# jbr_1986BE9x register map
Registers are 32-bit, access not given, no defined reset value unless marked. A register's access mark holds for its fields unless they carry their own. Addresses are absolute; registers are grouped by the start of their names; [hi:lo] are bit positions.

## IWDG
0x40068000 IWDG_KR 16-bit
  [15:0] KEY
0x40068004 IWDG_PR 16-bit
  [2:0] PR
0x40068008 IWDG_RLR 16-bit
  [11:0] RLR
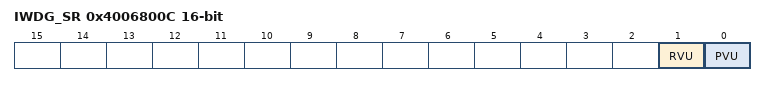
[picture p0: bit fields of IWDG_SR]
0x4006800C IWDG_SR 16-bit
  [1] RVU, [0] PVU

## WWDG
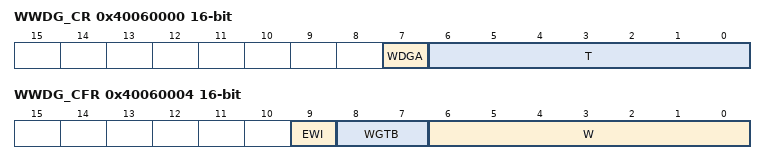
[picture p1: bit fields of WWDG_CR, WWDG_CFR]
0x40060000 WWDG_CR 16-bit
  [7] WDGA, [6:0] T
0x40060004 WWDG_CFR 16-bit
  [9] EWI, [8:7] WGTB, [6:0] W
0x40060008 WWDG_SR 16-bit
  [0] EWIF

## I2C
0x40050000 I2C_PRL
  [7:0] PR
0x40050004 I2C_PRH
  [7:0] PR
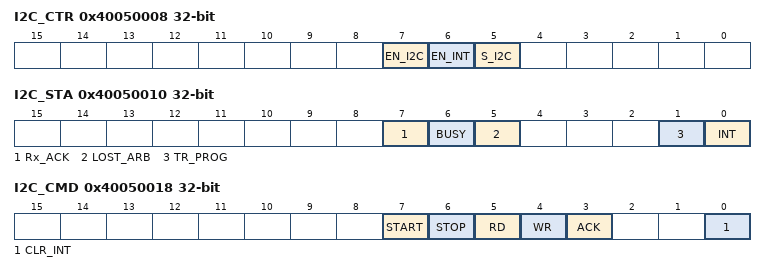
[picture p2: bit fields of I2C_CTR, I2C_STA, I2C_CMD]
0x40050008 I2C_CTR
  [7] EN_I2C, [6] EN_INT, [5] S_I2C
0x4005000C I2C_RXD
  [7:0] RXD
0x40050010 I2C_STA
  [7] Rx_ACK, [6] BUSY, [5] LOST_ARB, [1] TR_PROG, [0] INT
0x40050014 I2C_TXD
  [7:0] TXD
0x40050018 I2C_CMD
  [7] START, [6] STOP, [5] RD, [4] WR, [3] ACK, [0] CLR_INT

## SSP1
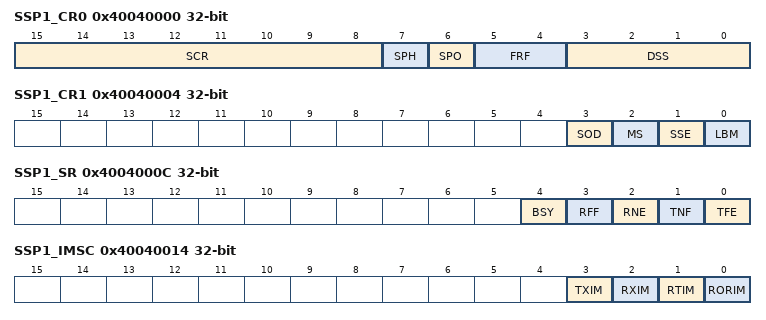
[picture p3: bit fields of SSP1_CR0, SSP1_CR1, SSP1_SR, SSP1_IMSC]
0x40040000 SSP1_CR0
  [15:8] SCR, [7] SPH, [6] SPO, [5:4] FRF, [3:0] DSS
0x40040004 SSP1_CR1
  [3] SOD, [2] MS, [1] SSE, [0] LBM
0x40040008 SSP1_DR
  [15:0] DATA
0x4004000C SSP1_SR
  [4] BSY, [3] RFF, [2] RNE, [1] TNF, [0] TFE
0x40040010 SSP1_CPSR
  [7:0] CPSDVSR
0x40040014 SSP1_IMSC
  [3] TXIM, [2] RXIM, [1] RTIM, [0] RORIM
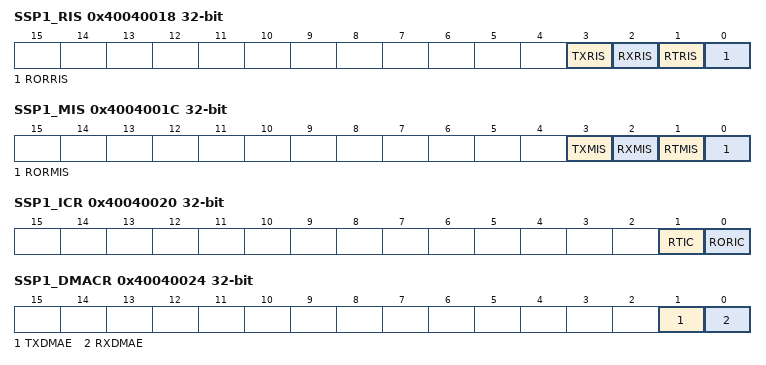
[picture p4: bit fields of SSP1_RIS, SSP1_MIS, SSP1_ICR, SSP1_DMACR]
0x40040018 SSP1_RIS
  [3] TXRIS, [2] RXRIS, [1] RTRIS, [0] RORRIS
0x4004001C SSP1_MIS
  [3] TXMIS, [2] RXMIS, [1] RTMIS, [0] RORMIS
0x40040020 SSP1_ICR
  [1] RTIC, [0] RORIC
0x40040024 SSP1_DMACR
  [1] TXDMAE, [0] RXDMAE

## SSP2
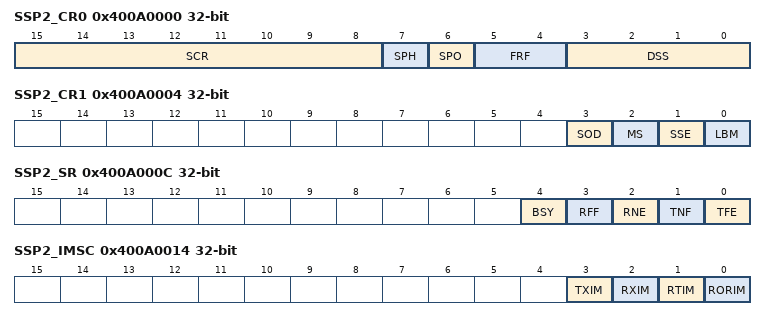
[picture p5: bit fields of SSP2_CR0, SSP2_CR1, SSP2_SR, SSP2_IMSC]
0x400A0000 SSP2_CR0
  [15:8] SCR, [7] SPH, [6] SPO, [5:4] FRF, [3:0] DSS
0x400A0004 SSP2_CR1
  [3] SOD, [2] MS, [1] SSE, [0] LBM
0x400A0008 SSP2_DR
  [15:0] DATA
0x400A000C SSP2_SR
  [4] BSY, [3] RFF, [2] RNE, [1] TNF, [0] TFE
0x400A0010 SSP2_CPSR
  [7:0] CPSDVSR
0x400A0014 SSP2_IMSC
  [3] TXIM, [2] RXIM, [1] RTIM, [0] RORIM
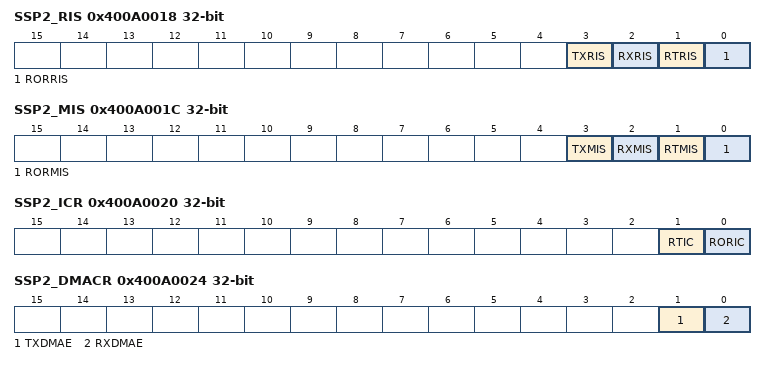
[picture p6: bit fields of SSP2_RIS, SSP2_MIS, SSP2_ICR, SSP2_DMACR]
0x400A0018 SSP2_RIS
  [3] TXRIS, [2] RXRIS, [1] RTRIS, [0] RORRIS
0x400A001C SSP2_MIS
  [3] TXMIS, [2] RXMIS, [1] RTMIS, [0] RORMIS
0x400A0020 SSP2_ICR
  [1] RTIC, [0] RORIC
0x400A0024 SSP2_DMACR
  [1] TXDMAE, [0] RXDMAE

## COMP
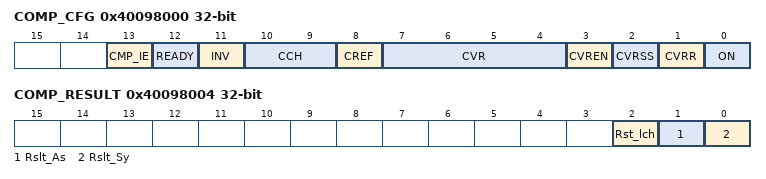
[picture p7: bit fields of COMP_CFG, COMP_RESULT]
0x40098000 COMP_CFG
  [13] CMP_IE, [12] READY, [11] INV, [10:9] CCH, [8] CREF, [7:4] CVR, [3] CVREN, [2] CVRSS, [1] CVRR, [0] ON
0x40098004 COMP_RESULT
  [2] Rst_lch, [1] Rslt_As, [0] Rslt_Sy
0x40098008 COMP_RESULT_LATCH
  [15:0] Rst_lch

## SFR
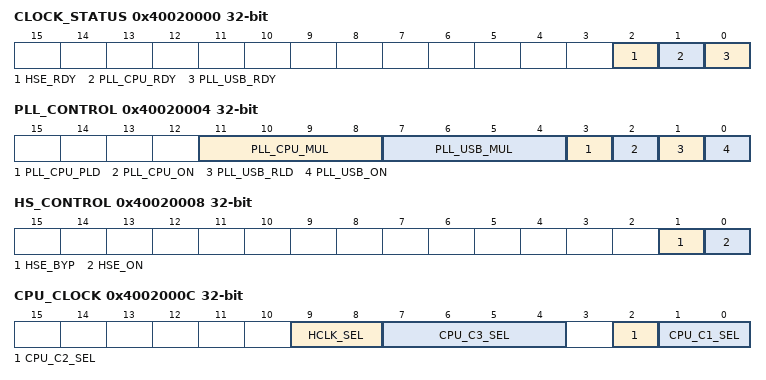
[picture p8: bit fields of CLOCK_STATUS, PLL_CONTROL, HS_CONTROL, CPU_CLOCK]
0x40020000 CLOCK_STATUS
  [2] HSE_RDY, [1] PLL_CPU_RDY, [0] PLL_USB_RDY
0x40020004 PLL_CONTROL
  [11:8] PLL_CPU_MUL, [7:4] PLL_USB_MUL, [3] PLL_CPU_PLD, [2] PLL_CPU_ON, [1] PLL_USB_RLD, [0] PLL_USB_ON
0x40020008 HS_CONTROL
  [1] HSE_BYP, [0] HSE_ON
0x4002000C CPU_CLOCK
  [9:8] HCLK_SEL, [7:4] CPU_C3_SEL, [2] CPU_C2_SEL, [1:0] CPU_C1_SEL
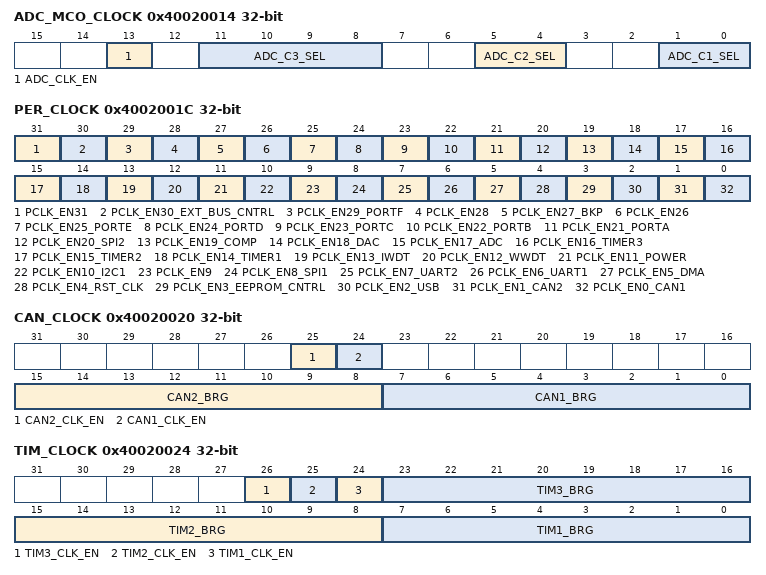
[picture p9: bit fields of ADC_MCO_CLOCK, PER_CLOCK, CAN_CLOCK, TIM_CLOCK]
0x40020014 ADC_MCO_CLOCK
  [13] ADC_CLK_EN, [11:8] ADC_C3_SEL, [5:4] ADC_C2_SEL, [1:0] ADC_C1_SEL
0x4002001C PER_CLOCK
  [31] PCLK_EN31, [30] PCLK_EN30_EXT_BUS_CNTRL, [29] PCLK_EN29_PORTF, [28] PCLK_EN28, [27] PCLK_EN27_BKP, [26] PCLK_EN26, [25] PCLK_EN25_PORTE, [24] PCLK_EN24_PORTD, [23] PCLK_EN23_PORTC, [22] PCLK_EN22_PORTB, [21] PCLK_EN21_PORTA, [20] PCLK_EN20_SPI2, [19] PCLK_EN19_COMP, [18] PCLK_EN18_DAC, [17] PCLK_EN17_ADC, [16] PCLK_EN16_TIMER3, [15] PCLK_EN15_TIMER2, [14] PCLK_EN14_TIMER1, [13] PCLK_EN13_IWDT, [12] PCLK_EN12_WWDT, [11] PCLK_EN11_POWER, [10] PCLK_EN10_I2C1, [9] PCLK_EN9, [8] PCLK_EN8_SPI1, [7] PCLK_EN7_UART2, [6] PCLK_EN6_UART1, [5] PCLK_EN5_DMA, [4] PCLK_EN4_RST_CLK, [3] PCLK_EN3_EEPROM_CNTRL, [2] PCLK_EN2_USB, [1] PCLK_EN1_CAN2, [0] PCLK_EN0_CAN1
0x40020020 CAN_CLOCK
  [25] CAN2_CLK_EN, [24] CAN1_CLK_EN, [15:8] CAN2_BRG, [7:0] CAN1_BRG
0x40020024 TIM_CLOCK
  [26] TIM3_CLK_EN, [25] TIM2_CLK_EN, [24] TIM1_CLK_EN, [23:16] TIM3_BRG, [15:8] TIM2_BRG, [7:0] TIM1_BRG
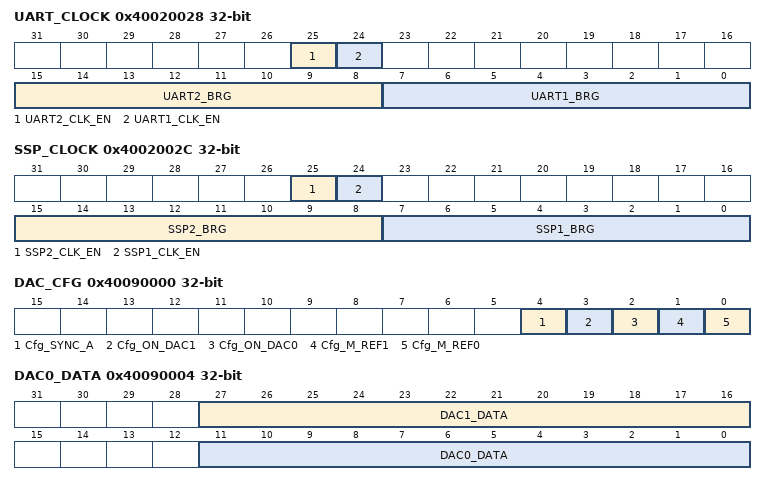
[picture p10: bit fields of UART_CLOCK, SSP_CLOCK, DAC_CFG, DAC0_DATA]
0x40020028 UART_CLOCK
  [25] UART2_CLK_EN, [24] UART1_CLK_EN, [15:8] UART2_BRG, [7:0] UART1_BRG
0x4002002C SSP_CLOCK
  [25] SSP2_CLK_EN, [24] SSP1_CLK_EN, [15:8] SSP2_BRG, [7:0] SSP1_BRG
0x40028008 CTRL_BASE_PTR
  [31:10] CTRL_BASE_PTR
0x4002800C ALT_CTRL_BASE_PTR
0x4002804C ERR_CLR
  [0] ERR_CLR
0x40090000 DAC_CFG
  [4] Cfg_SYNC_A, [3] Cfg_ON_DAC1, [2] Cfg_ON_DAC0, [1] Cfg_M_REF1, [0] Cfg_M_REF0
0x40090004 DAC0_DATA
  [27:16] DAC1_DATA, [11:0] DAC0_DATA
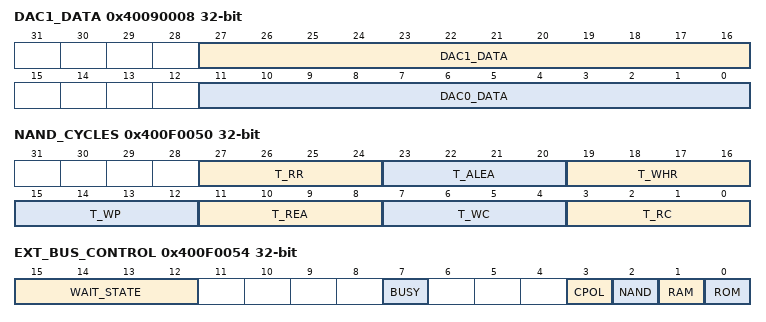
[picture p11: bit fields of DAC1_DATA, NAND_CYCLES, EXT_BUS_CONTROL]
0x40090008 DAC1_DATA
  [27:16] DAC1_DATA, [11:0] DAC0_DATA
0x400F0050 NAND_CYCLES
  [27:24] T_RR, [23:20] T_ALEA, [19:16] T_WHR, [15:12] T_WP, [11:8] T_REA, [7:4] T_WC, [3:0] T_RC
0x400F0054 EXT_BUS_CONTROL
  [15:12] WAIT_STATE, [7] BUSY, [3] CPOL, [2] NAND, [1] RAM, [0] ROM
